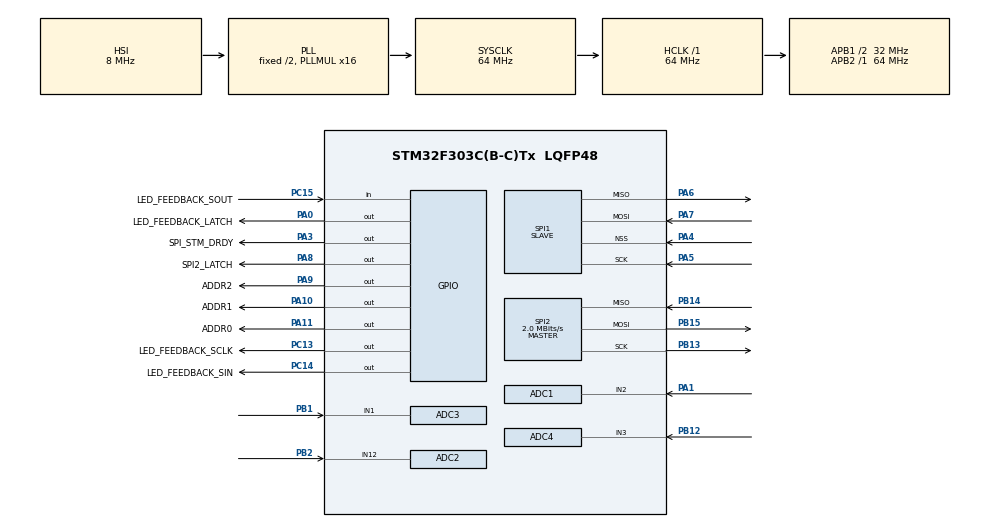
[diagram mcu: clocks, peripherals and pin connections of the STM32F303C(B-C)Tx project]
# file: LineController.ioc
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ADC1.Channel-0\#ChannelRegularConversion=ADC_CHANNEL_2
ADC1.ClockPrescaler=ADC_CLOCK_SYNC_PCLK_DIV2
ADC1.ContinuousConvMode=DISABLE
ADC1.DMAContinuousRequests=DISABLE
ADC1.DataAlign=ADC_DATAALIGN_RIGHT
ADC1.DiscontinuousConvMode=DISABLE
ADC1.EOCSelection=ADC_EOC_SINGLE_CONV
ADC1.EnableAnalogWatchDog1=false
ADC1.EnableAnalogWatchDog2=false
ADC1.EnableAnalogWatchDog3=false
ADC1.EnableInjectedConversion=ENABLE
ADC1.EnableRegularConversion=ENABLE
ADC1.ExternalTrigConv=ADC_SOFTWARE_START
ADC1.ExternalTrigConvEdge=ADC_EXTERNALTRIGCONVEDGE_NONE
ADC1.InjNumberOfConversion=0
ADC1.LowPowerAutoWait=DISABLE
ADC1.NbrOfConversion=1
ADC1.NbrOfConversionFlag=1
ADC1.Offset-0\#ChannelRegularConversion=0
ADC1.OffsetNumber-0\#ChannelRegularConversion=ADC_OFFSET_NONE
ADC1.Overrun=ADC_OVR_DATA_OVERWRITTEN
ADC1.Rank-0\#ChannelRegularConversion=1
ADC1.Resolution=ADC_RESOLUTION_8B
ADC1.SamplingTime-0\#ChannelRegularConversion=ADC_SAMPLETIME_4CYCLES_5
ADC1.ScanConvMode=ADC_SCAN_DISABLE
ADC1.master=1
ADC2.Channel-0\#ChannelRegularConversion=ADC_CHANNEL_12
ADC2.ClockPrescaler=ADC_CLOCK_SYNC_PCLK_DIV2
ADC2.ContinuousConvMode=DISABLE
ADC2.DMAContinuousRequests=DISABLE
ADC2.DataAlign=ADC_DATAALIGN_RIGHT
ADC2.DiscontinuousConvMode=DISABLE
ADC2.EOCSelection=ADC_EOC_SINGLE_CONV
ADC2.EnableAnalogWatchDog1=false
ADC2.EnableAnalogWatchDog2=false
ADC2.EnableAnalogWatchDog3=false
ADC2.EnableInjectedConversion=ENABLE
ADC2.EnableRegularConversion=ENABLE
ADC2.ExternalTrigConv=ADC_SOFTWARE_START
ADC2.ExternalTrigConvEdge=ADC_EXTERNALTRIGCONVEDGE_NONE
ADC2.InjNumberOfConversion=0
ADC2.LowPowerAutoWait=DISABLE
ADC2.NbrOfConversion=1
ADC2.NbrOfConversionFlag=1
ADC2.Offset-0\#ChannelRegularConversion=0
ADC2.OffsetNumber-0\#ChannelRegularConversion=ADC_OFFSET_NONE
ADC2.Overrun=ADC_OVR_DATA_OVERWRITTEN
ADC2.Rank-0\#ChannelRegularConversion=1
ADC2.Resolution=ADC_RESOLUTION_8B
ADC2.SamplingTime-0\#ChannelRegularConversion=ADC_SAMPLETIME_4CYCLES_5
ADC2.ScanConvMode=ADC_SCAN_DISABLE
ADC3.Channel-0\#ChannelRegularConversion=ADC_CHANNEL_1
ADC3.ClockPrescaler=ADC_CLOCK_SYNC_PCLK_DIV2
ADC3.NbrOfConversionFlag=1
ADC3.Offset-0\#ChannelRegularConversion=0
ADC3.OffsetNumber-0\#ChannelRegularConversion=ADC_OFFSET_NONE
ADC3.Rank-0\#ChannelRegularConversion=1
ADC3.Resolution=ADC_RESOLUTION_8B
ADC3.SamplingTime-0\#ChannelRegularConversion=ADC_SAMPLETIME_4CYCLES_5
ADC3.master=1
ADC4.Channel-0\#ChannelRegularConversion=ADC_CHANNEL_3
ADC4.ClockPrescaler=ADC_CLOCK_SYNC_PCLK_DIV2
ADC4.NbrOfConversionFlag=1
ADC4.Offset-0\#ChannelRegularConversion=0
ADC4.OffsetNumber-0\#ChannelRegularConversion=ADC_OFFSET_NONE
ADC4.Rank-0\#ChannelRegularConversion=1
ADC4.Resolution=ADC_RESOLUTION_8B
ADC4.SamplingTime-0\#ChannelRegularConversion=ADC_SAMPLETIME_4CYCLES_5
Mcu.Family=STM32F3
Mcu.Name=STM32F303C(B-C)Tx
Mcu.Package=LQFP48
NVIC.ADC1_2_IRQn=true\:0\:0\:false\:false\:true\:true
NVIC.ADC3_IRQn=true\:0\:0\:false\:false\:true\:true
NVIC.ADC4_IRQn=true\:0\:0\:false\:false\:true\:true
NVIC.PriorityGroup=NVIC_PRIORITYGROUP_4
NVIC.SPI1_IRQn=true\:0\:0\:false\:false\:true\:true
NVIC.SPI2_IRQn=true\:0\:0\:false\:false\:true\:true
NVIC.TIM1_BRK_TIM15_IRQn=true\:0\:0\:false\:false\:true\:true
NVIC.TIM1_CC_IRQn=true\:0\:0\:false\:false\:true\:true
NVIC.TIM1_TRG_COM_TIM17_IRQn=true\:0\:0\:false\:false\:true\:true
NVIC.TIM1_UP_TIM16_IRQn=true\:0\:0\:false\:false\:true\:true
PA0.GPIO_Label=LED_FEEDBACK_LATCH
PA0.Signal=GPIO_Output
PA1.Mode=IN2-Single-Ended
PA1.Signal=ADC1_IN2
PA10.GPIO_Label=ADDR1
PA10.GPIO_Speed=GPIO_SPEED_FREQ_HIGH
PA10.Signal=GPIO_Output
PA11.GPIO_Label=ADDR0
PA11.GPIO_Speed=GPIO_SPEED_FREQ_HIGH
PA11.Signal=GPIO_Output
PA13.Mode=Serial_Wire
PA13.Signal=SYS_JTMS-SWDIO
PA14.Mode=Serial_Wire
PA14.Signal=SYS_JTCK-SWCLK
PA3.GPIO_Label=SPI_STM_DRDY
PA3.GPIO_Speed=GPIO_SPEED_FREQ_HIGH
PA3.Signal=GPIO_Output
PA4.Mode=NSS_Signal_Hard_Input
PA4.Signal=SPI1_NSS
PA5.GPIO_PuPd=GPIO_PULLDOWN
PA5.Mode=Full_Duplex_Slave
PA5.Signal=SPI1_SCK
PA6.Mode=Full_Duplex_Slave
PA6.Signal=SPI1_MISO
PA7.Mode=Full_Duplex_Slave
PA7.Signal=SPI1_MOSI
PA8.GPIO_Label=SPI2_LATCH
PA8.GPIO_Speed=GPIO_SPEED_FREQ_HIGH
PA8.Signal=GPIO_Output
PA9.GPIO_Label=ADDR2
PA9.GPIO_Speed=GPIO_SPEED_FREQ_HIGH
PA9.Signal=GPIO_Output
PB1.Mode=IN1-Single-Ended
PB1.Signal=ADC3_IN1
PB12.Mode=IN3-Single-Ended
PB12.Signal=ADC4_IN3
PB13.Mode=Full_Duplex_Master
PB13.Signal=SPI2_SCK
PB14.Mode=Full_Duplex_Master
PB14.Signal=SPI2_MISO
PB15.Mode=Full_Duplex_Master
PB15.Signal=SPI2_MOSI
PB2.Mode=IN12-Single-Ended
PB2.Signal=ADC2_IN12
PC13.GPIO_Label=LED_FEEDBACK_SCLK
PC13.Signal=GPIO_Output
PC14-OSC32_IN.GPIO_Label=LED_FEEDBACK_SIN
PC14-OSC32_IN.Signal=GPIO_Output
PC15-OSC32_OUT.GPIO_Label=LED_FEEDBACK_SOUT
PC15-OSC32_OUT.Signal=GPIO_Input
ProjectManager.HeapSize=0x200
ProjectManager.StackSize=0x400
ProjectManager.TargetToolchain=SW4STM32
RCC.AHBFreq_Value=64000000
RCC.APB1CLKDivider=RCC_HCLK_DIV2
RCC.APB1Freq_Value=32000000
RCC.APB1TimFreq_Value=64000000
RCC.APB2Freq_Value=64000000
RCC.APB2TimFreq_Value=64000000
RCC.CortexFreq_Value=64000000
RCC.HCLKFreq_Value=64000000
RCC.HSE_VALUE=8000000
RCC.HSI_VALUE=8000000
RCC.LSE_VALUE=32768
RCC.PLLMUL=RCC_PLL_MUL16
RCC.SYSCLKFreq_VALUE=64000000
RCC.SYSCLKSourceVirtual=RCC_SYSCLKSOURCE_PLLCLK
RCC.USBFreq_Value=64000000
SPI1.CLKPhase=SPI_PHASE_2EDGE
SPI1.CLKPolarity=SPI_POLARITY_HIGH
SPI1.DataSize=SPI_DATASIZE_8BIT
SPI1.Direction=SPI_DIRECTION_2LINES
SPI1.Mode=SPI_MODE_SLAVE
SPI1.VirtualNSS=VM_NSSHARD
SPI1.VirtualType=VM_SLAVE
SPI2.BaudRatePrescaler=SPI_BAUDRATEPRESCALER_16
SPI2.CLKPolarity=SPI_POLARITY_LOW
SPI2.CalculateBaudRate=2.0 MBits/s
SPI2.DataSize=SPI_DATASIZE_8BIT
SPI2.Direction=SPI_DIRECTION_2LINES
SPI2.Mode=SPI_MODE_MASTER
SPI2.VirtualType=VM_MASTER
TIM1.AutoReloadPreload=TIM_AUTORELOAD_PRELOAD_DISABLE
TIM1.Period=65535
VP_TIM1_VS_ClockSourceINT.Mode=Internal
VP_TIM1_VS_OPM.Mode=OPM_bit
board=LineController

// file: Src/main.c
/**
  ******************************************************************************
  * File Name          : main.c
  * Description        : Main program body
  ******************************************************************************
  ** This notice applies to any and all portions of this file
  * that are not between comment pairs USER CODE BEGIN and
  * USER CODE END. Other portions of this file, whether
  * inserted by the user or by software development tools
  * are owned by their respective copyright owners.
  *
  * COPYRIGHT(c) 2017 STMicroelectronics
  *
  * Redistribution and use in source and binary forms, with or without modification,
  * are permitted provided that the following conditions are met:
  *   1. Redistributions of source code must retain the above copyright notice,
  *      this list of conditions and the following disclaimer.
  *   2. Redistributions in binary form must reproduce the above copyright notice,
  *      this list of conditions and the following disclaimer in the documentation
  *      and/or other materials provided with the distribution.
  *   3. Neither the name of STMicroelectronics nor the names of its contributors
  *      may be used to endorse or promote products derived from this software
  *      without specific prior written permission.
  *
  * THIS SOFTWARE IS PROVIDED BY THE COPYRIGHT HOLDERS AND CONTRIBUTORS "AS IS"
  * AND ANY EXPRESS OR IMPLIED WARRANTIES, INCLUDING, BUT NOT LIMITED TO, THE
  * IMPLIED WARRANTIES OF MERCHANTABILITY AND FITNESS FOR A PARTICULAR PURPOSE ARE
  * DISCLAIMED. IN NO EVENT SHALL THE COPYRIGHT HOLDER OR CONTRIBUTORS BE LIABLE
  * FOR ANY DIRECT, INDIRECT, INCIDENTAL, SPECIAL, EXEMPLARY, OR CONSEQUENTIAL
  * DAMAGES (INCLUDING, BUT NOT LIMITED TO, PROCUREMENT OF SUBSTITUTE GOODS OR
  * SERVICES; LOSS OF USE, DATA, OR PROFITS; OR BUSINESS INTERRUPTION) HOWEVER
  * CAUSED AND ON ANY THEORY OF LIABILITY, WHETHER IN CONTRACT, STRICT LIABILITY,
  * OR TORT (INCLUDING NEGLIGENCE OR OTHERWISE) ARISING IN ANY WAY OUT OF THE USE
  * OF THIS SOFTWARE, EVEN IF ADVISED OF THE POSSIBILITY OF SUCH DAMAGE.
  *
  ******************************************************************************
  */
#include "main.h"
#include "stm32f3xx_hal.h"

/* USER CODE BEGIN Includes */

#include "lst_lineController.h"

/* USER CODE END Includes */

ADC_HandleTypeDef hadc1;
ADC_HandleTypeDef hadc2;
ADC_HandleTypeDef hadc3;
ADC_HandleTypeDef hadc4;

SPI_HandleTypeDef hspi1;
SPI_HandleTypeDef hspi2;

TIM_HandleTypeDef htim1;

/* USER CODE BEGIN PV */
/* Private variables ---------------------------------------------------------*/

/* USER CODE END PV */

void SystemClock_Config(void);
static void MX_GPIO_Init(void);
static void MX_ADC3_Init(void);
static void MX_ADC2_Init(void);
static void MX_ADC4_Init(void);
static void MX_ADC1_Init(void);
static void MX_SPI1_Init(void);
static void MX_SPI2_Init(void);
static void MX_TIM1_Init(void);

/* USER CODE BEGIN PFP */
/* Private function prototypes -----------------------------------------------*/

/* USER CODE END PFP */

int main(void)
{

  /* MCU Configuration----------------------------------------------------------*/

  /* Reset of all peripherals, Initializes the Flash interface and the Systick. */
  HAL_Init();

  /* Configure the system clock */
  SystemClock_Config();

  /* Initialize all configured peripherals */
  MX_GPIO_Init();
  MX_ADC3_Init();
  MX_ADC2_Init();
  MX_ADC4_Init();
  MX_ADC1_Init();
  MX_SPI1_Init();
  MX_SPI2_Init();
  MX_TIM1_Init();

  /* Infinite loop */
  while (1)
  {

  /* USER CODE BEGIN 3 */

	 lst_entry_point(); // never returns

  }
  /* USER CODE END 3 */

}

/** System Clock Configuration
*/
void SystemClock_Config(void)
{

  RCC_OscInitTypeDef RCC_OscInitStruct;
  RCC_ClkInitTypeDef RCC_ClkInitStruct;
  RCC_PeriphCLKInitTypeDef PeriphClkInit;

    /**Initializes the CPU, AHB and APB busses clocks
    */
  RCC_OscInitStruct.OscillatorType = RCC_OSCILLATORTYPE_HSI;
  RCC_OscInitStruct.HSIState = RCC_HSI_ON;
  RCC_OscInitStruct.HSICalibrationValue = 16;
  RCC_OscInitStruct.PLL.PLLState = RCC_PLL_ON;
  RCC_OscInitStruct.PLL.PLLSource = RCC_PLLSOURCE_HSI;
  RCC_OscInitStruct.PLL.PLLMUL = RCC_PLL_MUL16;
  if (HAL_RCC_OscConfig(&RCC_OscInitStruct) != HAL_OK)
  {
    _Error_Handler(__FILE__, __LINE__);
  }

    /**Initializes the CPU, AHB and APB busses clocks
    */
  RCC_ClkInitStruct.ClockType = RCC_CLOCKTYPE_HCLK|RCC_CLOCKTYPE_SYSCLK
                              |RCC_CLOCKTYPE_PCLK1|RCC_CLOCKTYPE_PCLK2;
  RCC_ClkInitStruct.SYSCLKSource = RCC_SYSCLKSOURCE_PLLCLK;
  RCC_ClkInitStruct.AHBCLKDivider = RCC_SYSCLK_DIV1;
  RCC_ClkInitStruct.APB1CLKDivider = RCC_HCLK_DIV2;
  RCC_ClkInitStruct.APB2CLKDivider = RCC_HCLK_DIV1;

  if (HAL_RCC_ClockConfig(&RCC_ClkInitStruct, FLASH_LATENCY_2) != HAL_OK)
  {
    _Error_Handler(__FILE__, __LINE__);
  }

  PeriphClkInit.PeriphClockSelection = RCC_PERIPHCLK_TIM1;
  PeriphClkInit.Tim1ClockSelection = RCC_TIM1CLK_HCLK;
  if (HAL_RCCEx_PeriphCLKConfig(&PeriphClkInit) != HAL_OK)
  {
    _Error_Handler(__FILE__, __LINE__);
  }

    /**Configure the Systick interrupt time
    */
  HAL_SYSTICK_Config(HAL_RCC_GetHCLKFreq()/1000);

    /**Configure the Systick
    */
  HAL_SYSTICK_CLKSourceConfig(SYSTICK_CLKSOURCE_HCLK);

  /* SysTick_IRQn interrupt configuration */
  HAL_NVIC_SetPriority(SysTick_IRQn, 0, 0);
}

/* ADC1 init function */
static void MX_ADC1_Init(void)
{

  ADC_MultiModeTypeDef multimode;
  ADC_ChannelConfTypeDef sConfig;

    /**Common config
    */
  hadc1.Instance = ADC1;
  hadc1.Init.ClockPrescaler = ADC_CLOCK_SYNC_PCLK_DIV2;
  hadc1.Init.Resolution = ADC_RESOLUTION_8B;
  hadc1.Init.ScanConvMode = ADC_SCAN_DISABLE;
  hadc1.Init.ContinuousConvMode = DISABLE;
  hadc1.Init.DiscontinuousConvMode = DISABLE;
  hadc1.Init.ExternalTrigConvEdge = ADC_EXTERNALTRIGCONVEDGE_NONE;
  hadc1.Init.ExternalTrigConv = ADC_SOFTWARE_START;
  hadc1.Init.DataAlign = ADC_DATAALIGN_RIGHT;
  hadc1.Init.NbrOfConversion = 1;
  hadc1.Init.DMAContinuousRequests = DISABLE;
  hadc1.Init.EOCSelection = ADC_EOC_SINGLE_CONV;
  hadc1.Init.LowPowerAutoWait = DISABLE;
  hadc1.Init.Overrun = ADC_OVR_DATA_OVERWRITTEN;
  if (HAL_ADC_Init(&hadc1) != HAL_OK)
  {
    _Error_Handler(__FILE__, __LINE__);
  }

    /**Configure the ADC multi-mode
    */
  multimode.Mode = ADC_MODE_INDEPENDENT;
  if (HAL_ADCEx_MultiModeConfigChannel(&hadc1, &multimode) != HAL_OK)
  {
    _Error_Handler(__FILE__, __LINE__);
  }

    /**Configure Regular Channel
    */
  sConfig.Channel = ADC_CHANNEL_2;
  sConfig.Rank = 1;
  sConfig.SingleDiff = ADC_SINGLE_ENDED;
  sConfig.SamplingTime = ADC_SAMPLETIME_4CYCLES_5;
  sConfig.OffsetNumber = ADC_OFFSET_NONE;
  sConfig.Offset = 0;
  if (HAL_ADC_ConfigChannel(&hadc1, &sConfig) != HAL_OK)
  {
    _Error_Handler(__FILE__, __LINE__);
  }

}

/* ADC2 init function */
static void MX_ADC2_Init(void)
{

  ADC_ChannelConfTypeDef sConfig;

    /**Common config
    */
  hadc2.Instance = ADC2;
  hadc2.Init.ClockPrescaler = ADC_CLOCK_SYNC_PCLK_DIV2;
  hadc2.Init.Resolution = ADC_RESOLUTION_8B;
  hadc2.Init.ScanConvMode = ADC_SCAN_DISABLE;
  hadc2.Init.ContinuousConvMode = DISABLE;
  hadc2.Init.DiscontinuousConvMode = DISABLE;
  hadc2.Init.ExternalTrigConvEdge = ADC_EXTERNALTRIGCONVEDGE_NONE;
  hadc2.Init.ExternalTrigConv = ADC_SOFTWARE_START;
  hadc2.Init.DataAlign = ADC_DATAALIGN_RIGHT;
  hadc2.Init.NbrOfConversion = 1;
  hadc2.Init.DMAContinuousRequests = DISABLE;
  hadc2.Init.EOCSelection = ADC_EOC_SINGLE_CONV;
  hadc2.Init.LowPowerAutoWait = DISABLE;
  hadc2.Init.Overrun = ADC_OVR_DATA_OVERWRITTEN;
  if (HAL_ADC_Init(&hadc2) != HAL_OK)
  {
    _Error_Handler(__FILE__, __LINE__);
  }

    /**Configure Regular Channel
    */
  sConfig.Channel = ADC_CHANNEL_12;
  sConfig.Rank = 1;
  sConfig.SingleDiff = ADC_SINGLE_ENDED;
  sConfig.SamplingTime = ADC_SAMPLETIME_4CYCLES_5;
  sConfig.OffsetNumber = ADC_OFFSET_NONE;
  sConfig.Offset = 0;
  if (HAL_ADC_ConfigChannel(&hadc2, &sConfig) != HAL_OK)
  {
    _Error_Handler(__FILE__, __LINE__);
  }

}

/* ADC3 init function */
static void MX_ADC3_Init(void)
{

  ADC_MultiModeTypeDef multimode;
  ADC_ChannelConfTypeDef sConfig;

    /**Common config
    */
  hadc3.Instance = ADC3;
  hadc3.Init.ClockPrescaler = ADC_CLOCK_SYNC_PCLK_DIV2;
  hadc3.Init.Resolution = ADC_RESOLUTION_8B;
  hadc3.Init.ScanConvMode = ADC_SCAN_DISABLE;
  hadc3.Init.ContinuousConvMode = DISABLE;
  hadc3.Init.DiscontinuousConvMode = DISABLE;
  hadc3.Init.ExternalTrigConvEdge = ADC_EXTERNALTRIGCONVEDGE_NONE;
  hadc3.Init.ExternalTrigConv = ADC_SOFTWARE_START;
  hadc3.Init.DataAlign = ADC_DATAALIGN_RIGHT;
  hadc3.Init.NbrOfConversion = 1;
  hadc3.Init.DMAContinuousRequests = DISABLE;
  hadc3.Init.EOCSelection = ADC_EOC_SINGLE_CONV;
  hadc3.Init.LowPowerAutoWait = DISABLE;
  hadc3.Init.Overrun = ADC_OVR_DATA_OVERWRITTEN;
  if (HAL_ADC_Init(&hadc3) != HAL_OK)
  {
    _Error_Handler(__FILE__, __LINE__);
  }

    /**Configure the ADC multi-mode
    */
  multimode.Mode = ADC_MODE_INDEPENDENT;
  if (HAL_ADCEx_MultiModeConfigChannel(&hadc3, &multimode) != HAL_OK)
  {
    _Error_Handler(__FILE__, __LINE__);
  }

    /**Configure Regular Channel
    */
  sConfig.Channel = ADC_CHANNEL_1;
  sConfig.Rank = 1;
  sConfig.SingleDiff = ADC_SINGLE_ENDED;
  sConfig.SamplingTime = ADC_SAMPLETIME_4CYCLES_5;
  sConfig.OffsetNumber = ADC_OFFSET_NONE;
  sConfig.Offset = 0;
  if (HAL_ADC_ConfigChannel(&hadc3, &sConfig) != HAL_OK)
  {
    _Error_Handler(__FILE__, __LINE__);
  }

}

/* ADC4 init function */
static void MX_ADC4_Init(void)
{

  ADC_ChannelConfTypeDef sConfig;

    /**Common config
    */
  hadc4.Instance = ADC4;
  hadc4.Init.ClockPrescaler = ADC_CLOCK_SYNC_PCLK_DIV2;
  hadc4.Init.Resolution = ADC_RESOLUTION_8B;
  hadc4.Init.ScanConvMode = ADC_SCAN_DISABLE;
  hadc4.Init.ContinuousConvMode = DISABLE;
  hadc4.Init.DiscontinuousConvMode = DISABLE;
  hadc4.Init.ExternalTrigConvEdge = ADC_EXTERNALTRIGCONVEDGE_NONE;
  hadc4.Init.ExternalTrigConv = ADC_SOFTWARE_START;
  hadc4.Init.DataAlign = ADC_DATAALIGN_RIGHT;
  hadc4.Init.NbrOfConversion = 1;
  hadc4.Init.DMAContinuousRequests = DISABLE;
  hadc4.Init.EOCSelection = ADC_EOC_SINGLE_CONV;
  hadc4.Init.LowPowerAutoWait = DISABLE;
  hadc4.Init.Overrun = ADC_OVR_DATA_OVERWRITTEN;
  if (HAL_ADC_Init(&hadc4) != HAL_OK)
  {
    _Error_Handler(__FILE__, __LINE__);
  }

    /**Configure Regular Channel
    */
  sConfig.Channel = ADC_CHANNEL_3;
  sConfig.Rank = 1;
  sConfig.SingleDiff = ADC_SINGLE_ENDED;
  sConfig.SamplingTime = ADC_SAMPLETIME_4CYCLES_5;
  sConfig.OffsetNumber = ADC_OFFSET_NONE;
  sConfig.Offset = 0;
  if (HAL_ADC_ConfigChannel(&hadc4, &sConfig) != HAL_OK)
  {
    _Error_Handler(__FILE__, __LINE__);
  }

}

/* SPI1 init function */
static void MX_SPI1_Init(void)
{

  /* SPI1 parameter configuration*/
  hspi1.Instance = SPI1;
  hspi1.Init.Mode = SPI_MODE_SLAVE;
  hspi1.Init.Direction = SPI_DIRECTION_2LINES;
  hspi1.Init.DataSize = SPI_DATASIZE_8BIT;
  hspi1.Init.CLKPolarity = SPI_POLARITY_HIGH;
  hspi1.Init.CLKPhase = SPI_PHASE_2EDGE;
  hspi1.Init.NSS = SPI_NSS_HARD_INPUT;
  hspi1.Init.FirstBit = SPI_FIRSTBIT_MSB;
  hspi1.Init.TIMode = SPI_TIMODE_DISABLE;
  hspi1.Init.CRCCalculation = SPI_CRCCALCULATION_DISABLE;
  hspi1.Init.CRCPolynomial = 7;
  hspi1.Init.CRCLength = SPI_CRC_LENGTH_DATASIZE;
  hspi1.Init.NSSPMode = SPI_NSS_PULSE_DISABLE;
  if (HAL_SPI_Init(&hspi1) != HAL_OK)
  {
    _Error_Handler(__FILE__, __LINE__);
  }

}

/* SPI2 init function */
static void MX_SPI2_Init(void)
{

  /* SPI2 parameter configuration*/
  hspi2.Instance = SPI2;
  hspi2.Init.Mode = SPI_MODE_MASTER;
  hspi2.Init.Direction = SPI_DIRECTION_2LINES;
  hspi2.Init.DataSize = SPI_DATASIZE_8BIT;
  hspi2.Init.CLKPolarity = SPI_POLARITY_LOW;
  hspi2.Init.CLKPhase = SPI_PHASE_1EDGE;
  hspi2.Init.NSS = SPI_NSS_SOFT;
  hspi2.Init.BaudRatePrescaler = SPI_BAUDRATEPRESCALER_16;
  hspi2.Init.FirstBit = SPI_FIRSTBIT_MSB;
  hspi2.Init.TIMode = SPI_TIMODE_DISABLE;
  hspi2.Init.CRCCalculation = SPI_CRCCALCULATION_DISABLE;
  hspi2.Init.CRCPolynomial = 7;
  hspi2.Init.CRCLength = SPI_CRC_LENGTH_DATASIZE;
  hspi2.Init.NSSPMode = SPI_NSS_PULSE_ENABLE;
  if (HAL_SPI_Init(&hspi2) != HAL_OK)
  {
    _Error_Handler(__FILE__, __LINE__);
  }

}

/* TIM1 init function */
static void MX_TIM1_Init(void)
{

  TIM_ClockConfigTypeDef sClockSourceConfig;
  TIM_MasterConfigTypeDef sMasterConfig;

  htim1.Instance = TIM1;
  htim1.Init.Prescaler = 0;
  htim1.Init.CounterMode = TIM_COUNTERMODE_UP;
  htim1.Init.Period = 65535;
  htim1.Init.ClockDivision = TIM_CLOCKDIVISION_DIV1;
  htim1.Init.RepetitionCounter = 0;
  htim1.Init.AutoReloadPreload = TIM_AUTORELOAD_PRELOAD_DISABLE;
  if (HAL_TIM_Base_Init(&htim1) != HAL_OK)
  {
    _Error_Handler(__FILE__, __LINE__);
  }

  sClockSourceConfig.ClockSource = TIM_CLOCKSOURCE_INTERNAL;
  if (HAL_TIM_ConfigClockSource(&htim1, &sClockSourceConfig) != HAL_OK)
  {
    _Error_Handler(__FILE__, __LINE__);
  }

  if (HAL_TIM_OnePulse_Init(&htim1, TIM_OPMODE_SINGLE) != HAL_OK)
  {
    _Error_Handler(__FILE__, __LINE__);
  }

  sMasterConfig.MasterOutputTrigger = TIM_TRGO_RESET;
  sMasterConfig.MasterOutputTrigger2 = TIM_TRGO2_RESET;
  sMasterConfig.MasterSlaveMode = TIM_MASTERSLAVEMODE_DISABLE;
  if (HAL_TIMEx_MasterConfigSynchronization(&htim1, &sMasterConfig) != HAL_OK)
  {
    _Error_Handler(__FILE__, __LINE__);
  }

}

/** Configure pins as
        * Analog
        * Input
        * Output
        * EVENT_OUT
        * EXTI
*/
static void MX_GPIO_Init(void)
{

  GPIO_InitTypeDef GPIO_InitStruct;

  /* GPIO Ports Clock Enable */
  __HAL_RCC_GPIOC_CLK_ENABLE();
  __HAL_RCC_GPIOA_CLK_ENABLE();
  __HAL_RCC_GPIOB_CLK_ENABLE();

  /*Configure GPIO pin Output Level */
  HAL_GPIO_WritePin(GPIOC, LED_FEEDBACK_SCLK_Pin|LED_FEEDBACK_SIN_Pin, GPIO_PIN_RESET);

  /*Configure GPIO pin Output Level */
  HAL_GPIO_WritePin(GPIOA, LED_FEEDBACK_LATCH_Pin|SPI_STM_DRDY_Pin|SPI2_LATCH_Pin|ADDR2_Pin
                          |ADDR1_Pin|ADDR0_Pin, GPIO_PIN_RESET);

  /*Configure GPIO pins : LED_FEEDBACK_SCLK_Pin LED_FEEDBACK_SIN_Pin */
  GPIO_InitStruct.Pin = LED_FEEDBACK_SCLK_Pin|LED_FEEDBACK_SIN_Pin;
  GPIO_InitStruct.Mode = GPIO_MODE_OUTPUT_PP;
  GPIO_InitStruct.Pull = GPIO_NOPULL;
  GPIO_InitStruct.Speed = GPIO_SPEED_FREQ_LOW;
  HAL_GPIO_Init(GPIOC, &GPIO_InitStruct);

  /*Configure GPIO pin : LED_FEEDBACK_SOUT_Pin */
  GPIO_InitStruct.Pin = LED_FEEDBACK_SOUT_Pin;
  GPIO_InitStruct.Mode = GPIO_MODE_INPUT;
  GPIO_InitStruct.Pull = GPIO_NOPULL;
  HAL_GPIO_Init(LED_FEEDBACK_SOUT_GPIO_Port, &GPIO_InitStruct);

  /*Configure GPIO pin : LED_FEEDBACK_LATCH_Pin */
  GPIO_InitStruct.Pin = LED_FEEDBACK_LATCH_Pin;
  GPIO_InitStruct.Mode = GPIO_MODE_OUTPUT_PP;
  GPIO_InitStruct.Pull = GPIO_NOPULL;
  GPIO_InitStruct.Speed = GPIO_SPEED_FREQ_LOW;
  HAL_GPIO_Init(LED_FEEDBACK_LATCH_GPIO_Port, &GPIO_InitStruct);

  /*Configure GPIO pins : SPI_STM_DRDY_Pin SPI2_LATCH_Pin ADDR2_Pin ADDR1_Pin
                           ADDR0_Pin */
  GPIO_InitStruct.Pin = SPI_STM_DRDY_Pin|SPI2_LATCH_Pin|ADDR2_Pin|ADDR1_Pin
                          |ADDR0_Pin;
  GPIO_InitStruct.Mode = GPIO_MODE_OUTPUT_PP;
  GPIO_InitStruct.Pull = GPIO_NOPULL;
  GPIO_InitStruct.Speed = GPIO_SPEED_FREQ_HIGH;
  HAL_GPIO_Init(GPIOA, &GPIO_InitStruct);

}

void _Error_Handler(char * file, int line)
{
  while(1)
  {
  }
}

/************************ (C) COPYRIGHT STMicroelectronics *****END OF FILE****/
